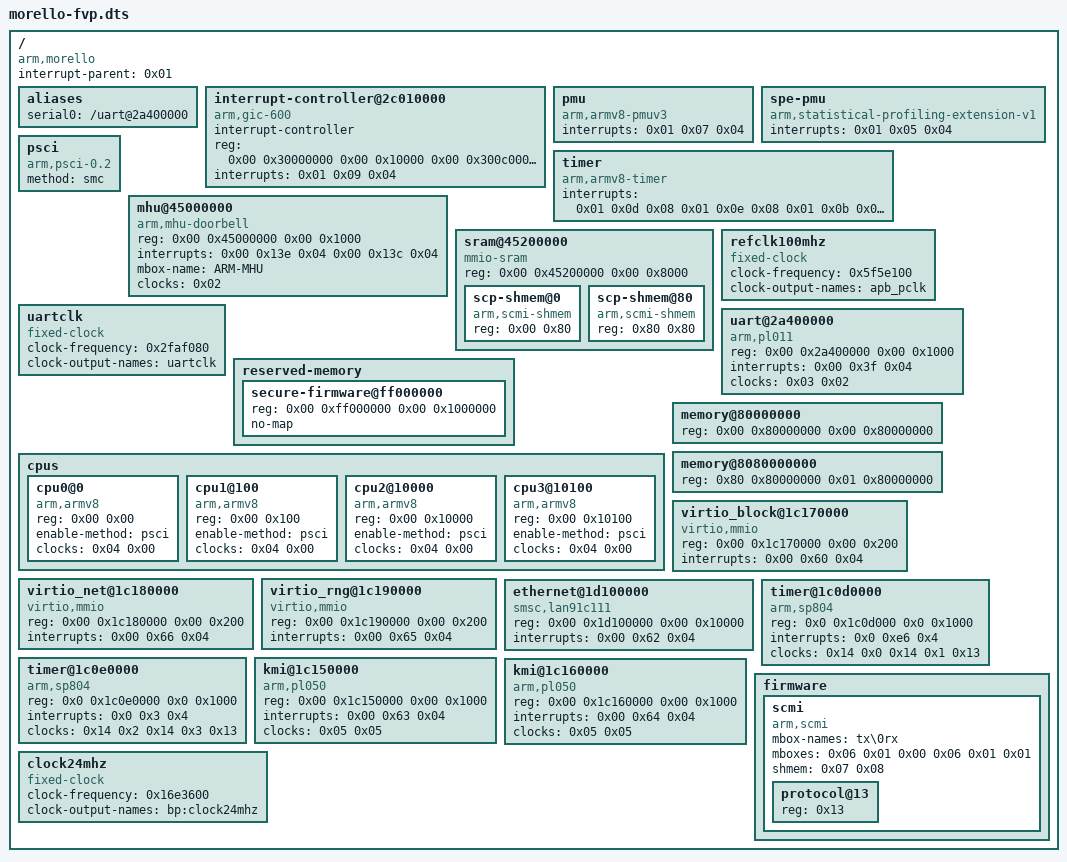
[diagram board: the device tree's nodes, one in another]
/*
 * Copyright (c) 2020-2023, Arm Limited. All rights reserved.
 *
 * SPDX-License-Identifier: BSD-3-Clause
 */

/dts-v1/;

/ {
	compatible = "arm,morello";
	interrupt-parent = <0x01>;
	#address-cells = <0x02>;
	#size-cells = <0x02>;

	aliases {
		serial0 = "/uart@2a400000";
	};

	interrupt-controller@2c010000 {
		compatible = "arm,gic-600\0arm,gic-v3";
		#address-cells = <0x02>;
		#interrupt-cells = <0x03>;
		#size-cells = <0x02>;
		ranges;
		interrupt-controller;
		reg = <0x00 0x30000000 0x00 0x10000 0x00 0x300c0000 0x00 0x80000>;
		interrupts = <0x01 0x09 0x04>;
		phandle = <0x01>;
	};

	pmu {
		compatible = "arm,armv8-pmuv3";
		interrupts = <0x01 0x07 0x04>;
	};

	spe-pmu {
		compatible = "arm,statistical-profiling-extension-v1";
		interrupts = <0x01 0x05 0x04>;
	};

	psci {
		compatible = "arm,psci-0.2";
		method = "smc";
	};

	timer {
		compatible = "arm,armv8-timer";
		interrupts = <0x01 0x0d 0x08 0x01 0x0e 0x08 0x01 0x0b 0x08 0x01 0x0a 0x08>;
	};

	mhu@45000000 {
		compatible = "arm,mhu-doorbell\0arm,primecell";
		reg = <0x00 0x45000000 0x00 0x1000>;
		interrupts = <0x00 0x13e 0x04 0x00 0x13c 0x04>;
		interrupt-names = "mhu_lpri_rx\0mhu_hpri_rx";
		#mbox-cells = <0x02>;
		mbox-name = "ARM-MHU";
		clocks = <0x02>;
		clock-names = "apb_pclk";
		phandle = <0x06>;
	};

	sram@45200000 {
		compatible = "mmio-sram";
		reg = <0x00 0x45200000 0x00 0x8000>;
		#address-cells = <0x01>;
		#size-cells = <0x01>;
		ranges = <0x00 0x00 0x45200000 0x8000>;

		scp-shmem@0 {
			compatible = "arm,scmi-shmem";
			reg = <0x00 0x80>;
			phandle = <0x07>;
		};

		scp-shmem@80 {
			compatible = "arm,scmi-shmem";
			reg = <0x80 0x80>;
			phandle = <0x08>;
		};
	};

	refclk100mhz {
		compatible = "fixed-clock";
		#clock-cells = <0x00>;
		clock-frequency = <0x5f5e100>;
		clock-output-names = "apb_pclk";
		phandle = <0x02>;
	};

	uartclk {
		compatible = "fixed-clock";
		#clock-cells = <0x00>;
		clock-frequency = <0x2faf080>;
		clock-output-names = "uartclk";
		phandle = <0x03>;
	};

	uart@2a400000 {
		compatible = "arm,pl011\0arm,primecell";
		reg = <0x00 0x2a400000 0x00 0x1000>;
		interrupts = <0x00 0x3f 0x04>;
		clocks = <0x03 0x02>;
		clock-names = "uartclk\0apb_pclk";
		status = "okay";
	};

	reserved-memory {
		#address-cells = <0x02>;
		#size-cells = <0x02>;
		ranges;

		secure-firmware@ff000000 {
			reg = <0x00 0xff000000 0x00 0x1000000>;
			no-map;
		};
	};

	cpus {
		#address-cells = <0x02>;
		#size-cells = <0x00>;

		cpu0@0 {
			compatible = "arm,armv8";
			reg = <0x00 0x00>;
			device_type = "cpu";
			enable-method = "psci";
			clocks = <0x04 0x00>;
		};

		cpu1@100 {
			compatible = "arm,armv8";
			reg = <0x00 0x100>;
			device_type = "cpu";
			enable-method = "psci";
			clocks = <0x04 0x00>;
		};

		cpu2@10000 {
			compatible = "arm,armv8";
			reg = <0x00 0x10000>;
			device_type = "cpu";
			enable-method = "psci";
			clocks = <0x04 0x00>;
		};

		cpu3@10100 {
			compatible = "arm,armv8";
			reg = <0x00 0x10100>;
			device_type = "cpu";
			enable-method = "psci";
			clocks = <0x04 0x00>;
		};
	};

	memory@80000000 {
		#address-cells = <0x02>;
		#size-cells = <0x02>;
		device_type = "memory";
		reg = <0x00 0x80000000 0x00 0x80000000>;
	};

	memory@8080000000 {
		#address-cells = <0x02>;
		#size-cells = <0x02>;
		device_type = "memory";
		reg = <0x80 0x80000000 0x01 0x80000000>;
	};

	virtio_block@1c170000 {
		compatible = "virtio,mmio";
		reg = <0x00 0x1c170000 0x00 0x200>;
		interrupts = <0x00 0x60 0x04>;
	};

	virtio_net@1c180000 {
		compatible = "virtio,mmio";
		reg = <0x00 0x1c180000 0x00 0x200>;
		interrupts = <0x00 0x66 0x04>;
	};

	virtio_rng@1c190000 {
		compatible = "virtio,mmio";
		reg = <0x00 0x1c190000 0x00 0x200>;
		interrupts = <0x00 0x65 0x04>;
	};

	ethernet@1d100000 {
		compatible = "smsc,lan91c111";
		reg = <0x00 0x1d100000 0x00 0x10000>;
		interrupts = <0x00 0x62 0x04>;
	};

	timer@1c0d0000 {
		compatible = "arm,sp804", "arm,primecell";
		reg = <0x0 0x1c0d000 0x0 0x1000>;
		interrupts = <0x0 0xe6 0x4>;
		clocks = <0x14 0x0 0x14 0x1 0x13>;
		clock-names = "timclken1", "timclken2", "apb_pclk";
	};

	timer@1c0e0000 {
		compatible = "arm,sp804", "arm,primecell";
		reg = <0x0 0x1c0e0000 0x0 0x1000>;
		interrupts = <0x0 0x3 0x4>;
		clocks = <0x14 0x2 0x14 0x3 0x13>;
		clock-names = "timclken1", "timclken2", "apb_pclk";
	};

	kmi@1c150000 {
		compatible = "arm,pl050\0arm,primecell";
		reg = <0x00 0x1c150000 0x00 0x1000>;
		interrupts = <0x00 0x63 0x04>;
		clocks = <0x05 0x05>;
		clock-names = "KMIREFCLK\0apb_pclk";
	};

	kmi@1c160000 {
		compatible = "arm,pl050\0arm,primecell";
		reg = <0x00 0x1c160000 0x00 0x1000>;
		interrupts = <0x00 0x64 0x04>;
		clocks = <0x05 0x05>;
		clock-names = "KMIREFCLK\0apb_pclk";
	};

	firmware {

		scmi {
			compatible = "arm,scmi";
			mbox-names = "tx\0rx";
			mboxes = <0x06 0x01 0x00 0x06 0x01 0x01>;
			shmem = <0x07 0x08>;
			#address-cells = <0x01>;
			#size-cells = <0x00>;

			protocol@13 {
				reg = <0x13>;
				#clock-cells = <0x01>;
				phandle = <0x04>;
			};
		};
	};

	clock24mhz {
		compatible = "fixed-clock";
		#clock-cells = <0x00>;
		clock-frequency = <0x16e3600>;
		clock-output-names = "bp:clock24mhz";
		phandle = <0x05>;
	};
};
